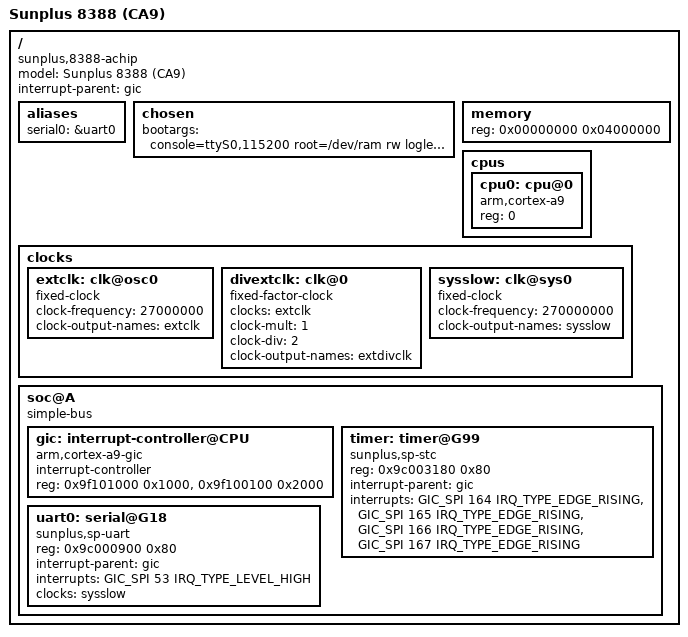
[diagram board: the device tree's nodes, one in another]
/dts-v1/;

#include "skeleton.dtsi"

#include <dt-bindings/interrupt-controller/arm-gic.h>

/ {
	model = "Sunplus 8388 (CA9)";
	compatible = "sunplus,8388-achip";

	interrupt-parent = <&gic>;

	aliases {
		serial0 = &uart0;
	};

	chosen {
		bootargs = "console=ttyS0,115200 root=/dev/ram rw loglevel=8 earlyprintk";
	};

	memory {
		reg = <0x00000000 0x04000000>;
	};

	cpus {
		#address-cells = <1>;
		#size-cells = <0>;

		cpu0: cpu@0 {
			compatible = "arm,cortex-a9";
			device_type = "cpu";
			reg = <0>;
		};
	};

	clocks {
                #address-cells = <1>;
                #size-cells = <1>;
                ranges;

		extclk: clk@osc0 {
			#clock-cells = <0>;
			compatible = "fixed-clock";
			clock-frequency = <27000000>;
			clock-output-names = "extclk";
		};

		divextclk: clk@0 {
			#clock-cells = <0>;
			compatible = "fixed-factor-clock";
			clocks  = <&extclk>;
			clock-mult = <1>;
			clock-div = <2>;
			clock-output-names = "extdivclk";
		};

		sysslow: clk@sys0 {
			#clock-cells = <0>;
			compatible = "fixed-clock";
			clock-frequency = <270000000>;
			clock-output-names = "sysslow";
		};
	};

	soc@A {
		compatible = "simple-bus";
		#address-cells = <1>;
		#size-cells = <1>;
		ranges;

		gic: interrupt-controller@CPU {
			compatible = "arm,cortex-a9-gic";
			interrupt-controller;
			#interrupt-cells = <3>;
			reg = <0x9f101000 0x1000>,
				<0x9f100100 0x2000>;
		};

#if 0
		/* STC */
		timer: timer@G12 {
			compatible = "sunplus,sp-stc";
			reg = <0x9c000600 0x80>;
			interrupt-parent = <&gic>;
			interrupts =
				<GIC_SPI 151 IRQ_TYPE_EDGE_RISING>, /* timer0 */
				<GIC_SPI 152 IRQ_TYPE_EDGE_RISING>, /* timer1 */
				<GIC_SPI 153 IRQ_TYPE_EDGE_RISING>, /* timer2 */
				<GIC_SPI 154 IRQ_TYPE_EDGE_RISING>; /* timer3 */
		};
#else
		/* STC_AV2 */
		timer: timer@G99 {
			compatible = "sunplus,sp-stc";
			reg = <0x9c003180 0x80>;
			interrupt-parent = <&gic>;
			interrupts =
				<GIC_SPI 164 IRQ_TYPE_EDGE_RISING>, /* timer0 */
				<GIC_SPI 165 IRQ_TYPE_EDGE_RISING>, /* timer1 */
				<GIC_SPI 166 IRQ_TYPE_EDGE_RISING>, /* timer2 */
				<GIC_SPI 167 IRQ_TYPE_EDGE_RISING>; /* timer3 */
		};
#endif

		uart0: serial@G18 {
			compatible = "sunplus,sp-uart";
			reg = <0x9c000900 0x80>;
			interrupt-parent = <&gic>;
			interrupts = <GIC_SPI 53 IRQ_TYPE_LEVEL_HIGH>;
			clocks = <&sysslow>;
		};
	};
};
